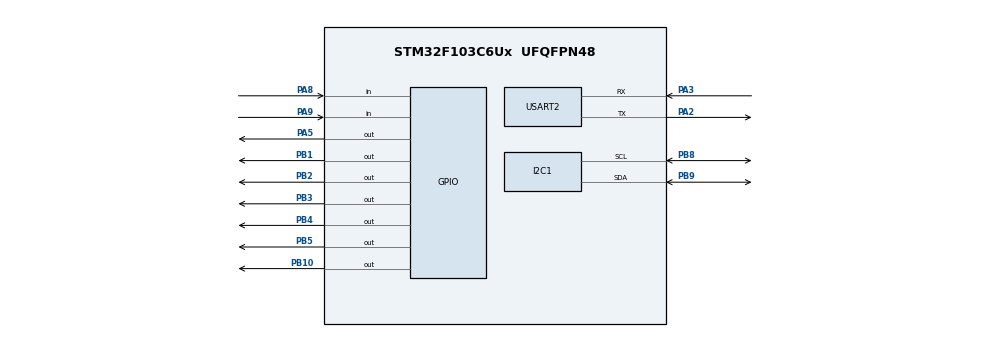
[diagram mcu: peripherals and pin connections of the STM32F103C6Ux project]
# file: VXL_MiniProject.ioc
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Mcu.Family=STM32F1
Mcu.Name=STM32F103C6Ux
Mcu.Package=UFQFPN48
NVIC.PriorityGroup=NVIC_PRIORITYGROUP_4
NVIC.TIM2_IRQn=true\:0\:0\:false\:false\:true\:true\:true\:true
NVIC.USART2_IRQn=true\:0\:0\:false\:false\:true\:true\:true\:true
PA2.Mode=Asynchronous
PA2.Signal=USART2_TX
PA3.Mode=Asynchronous
PA3.Signal=USART2_RX
PA5.Signal=GPIO_Output
PA8.GPIO_PuPd=GPIO_PULLUP
PA8.Signal=GPIO_Input
PA9.GPIO_PuPd=GPIO_PULLUP
PA9.Signal=GPIO_Input
PB1.Signal=GPIO_Output
PB10.Signal=GPIO_Output
PB2.Signal=GPIO_Output
PB3.Signal=GPIO_Output
PB4.Signal=GPIO_Output
PB5.Signal=GPIO_Output
PB8.Mode=I2C
PB8.Signal=I2C1_SCL
PB9.Mode=I2C
PB9.Signal=I2C1_SDA
ProjectManager.HeapSize=0x200
ProjectManager.StackSize=0x400
ProjectManager.TargetToolchain=STM32CubeIDE
RCC.APB1Freq_Value=8000000
RCC.APB2Freq_Value=8000000
TIM2.Period=9
TIM2.Prescaler=7999
USART2.VirtualMode=VM_ASYNC
VP_SYS_VS_ND.Mode=No_Debug
VP_TIM2_VS_ClockSourceINT.Mode=Internal
board=custom

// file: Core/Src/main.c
/* USER CODE BEGIN Header */
/**
  ******************************************************************************
  * @file           : main.c
  * @brief          : Main program body
  ******************************************************************************
  * @attention
  *
  * Copyright (c) 2025 STMicroelectronics.
  * All rights reserved.
  *
  * This software is licensed under terms that can be found in the LICENSE file
  * in the root directory of this software component.
  * If no LICENSE file comes with this software, it is provided AS-IS.
  *
  ******************************************************************************
  */
/* USER CODE END Header */
#include "main.h"

/* USER CODE BEGIN Includes */
#include "global.h"
/* USER CODE END Includes */

/* USER CODE BEGIN PD */
#define MyI2C_LCD I2C_LCD_1
/* USER CODE END PD */

I2C_HandleTypeDef hi2c1;

TIM_HandleTypeDef htim2;

UART_HandleTypeDef huart2;

void SystemClock_Config(void);
static void MX_GPIO_Init(void);
static void MX_TIM2_Init(void);
static void MX_USART2_UART_Init(void);
static void MX_I2C1_Init(void);

int main(void)
{

  /* MCU Configuration--------------------------------------------------------*/

  /* Reset of all peripherals, Initializes the Flash interface and the Systick. */
  HAL_Init();

  /* Configure the system clock */
  SystemClock_Config();

  /* Initialize all configured peripherals */
  MX_GPIO_Init();
  MX_TIM2_Init();
  MX_USART2_UART_Init();
  MX_I2C1_Init();
  /* USER CODE BEGIN 2 */
  HAL_TIM_Base_Start_IT (&htim2);
//  HAL_UART_Receive_IT(&huart2, rx_data, 1);
  /* USER CODE END 2 */

  /* Infinite loop */
  /* USER CODE BEGIN WHILE */
  SCH_Init();
  SCH_Add_Task(Run_Traffic_Light, 0, 100);
  HAL_GPIO_WritePin(GPIOA, LED_PINK, SET);
  while (1)
  {
//	  if (isButtonPressed(0) == 1){
//		  HAL_GPIO_TogglePin(GPIOA, LED_PINK);
//	  }
	  //HAL_GPIO_WritePin(GPIOA, LED_PINK, HAL_GPIO_ReadPin(GPIOA, UP_BUTTON));
//	  if (isButtonPressed(0) == 1){
//	  		  HAL_GPIO_TogglePin(GPIOA, LED_PINK);
//	  		  button_flag[0] = 0;
//	  	  }
	  SCH_Dispatch_Tasks();
//	  HAL_Delay(1000);
    /* USER CODE END WHILE */

  }
}

void SystemClock_Config(void)
{
  RCC_OscInitTypeDef RCC_OscInitStruct = {0};
  RCC_ClkInitTypeDef RCC_ClkInitStruct = {0};

  /** Initializes the RCC Oscillators according to the specified parameters
  * in the RCC_OscInitTypeDef structure.
  */
  RCC_OscInitStruct.OscillatorType = RCC_OSCILLATORTYPE_HSI;
  RCC_OscInitStruct.HSIState = RCC_HSI_ON;
  RCC_OscInitStruct.HSICalibrationValue = RCC_HSICALIBRATION_DEFAULT;
  RCC_OscInitStruct.PLL.PLLState = RCC_PLL_NONE;
  if (HAL_RCC_OscConfig(&RCC_OscInitStruct) != HAL_OK)
  {
    Error_Handler();
  }

  /** Initializes the CPU, AHB and APB buses clocks
  */
  RCC_ClkInitStruct.ClockType = RCC_CLOCKTYPE_HCLK|RCC_CLOCKTYPE_SYSCLK
                              |RCC_CLOCKTYPE_PCLK1|RCC_CLOCKTYPE_PCLK2;
  RCC_ClkInitStruct.SYSCLKSource = RCC_SYSCLKSOURCE_HSI;
  RCC_ClkInitStruct.AHBCLKDivider = RCC_SYSCLK_DIV1;
  RCC_ClkInitStruct.APB1CLKDivider = RCC_HCLK_DIV1;
  RCC_ClkInitStruct.APB2CLKDivider = RCC_HCLK_DIV1;

  if (HAL_RCC_ClockConfig(&RCC_ClkInitStruct, FLASH_LATENCY_0) != HAL_OK)
  {
    Error_Handler();
  }
}

static void MX_I2C1_Init(void)
{

  hi2c1.Instance = I2C1;
  hi2c1.Init.ClockSpeed = 100000;
  hi2c1.Init.DutyCycle = I2C_DUTYCYCLE_2;
  hi2c1.Init.OwnAddress1 = 0;
  hi2c1.Init.AddressingMode = I2C_ADDRESSINGMODE_7BIT;
  hi2c1.Init.DualAddressMode = I2C_DUALADDRESS_DISABLE;
  hi2c1.Init.OwnAddress2 = 0;
  hi2c1.Init.GeneralCallMode = I2C_GENERALCALL_DISABLE;
  hi2c1.Init.NoStretchMode = I2C_NOSTRETCH_DISABLE;
  if (HAL_I2C_Init(&hi2c1) != HAL_OK)
  {
    Error_Handler();
  }

}

static void MX_TIM2_Init(void)
{

  TIM_ClockConfigTypeDef sClockSourceConfig = {0};
  TIM_MasterConfigTypeDef sMasterConfig = {0};

  htim2.Instance = TIM2;
  htim2.Init.Prescaler = 7999;
  htim2.Init.CounterMode = TIM_COUNTERMODE_UP;
  htim2.Init.Period = 9;
  htim2.Init.ClockDivision = TIM_CLOCKDIVISION_DIV1;
  htim2.Init.AutoReloadPreload = TIM_AUTORELOAD_PRELOAD_DISABLE;
  if (HAL_TIM_Base_Init(&htim2) != HAL_OK)
  {
    Error_Handler();
  }
  sClockSourceConfig.ClockSource = TIM_CLOCKSOURCE_INTERNAL;
  if (HAL_TIM_ConfigClockSource(&htim2, &sClockSourceConfig) != HAL_OK)
  {
    Error_Handler();
  }
  sMasterConfig.MasterOutputTrigger = TIM_TRGO_RESET;
  sMasterConfig.MasterSlaveMode = TIM_MASTERSLAVEMODE_DISABLE;
  if (HAL_TIMEx_MasterConfigSynchronization(&htim2, &sMasterConfig) != HAL_OK)
  {
    Error_Handler();
  }

}

static void MX_USART2_UART_Init(void)
{

  huart2.Instance = USART2;
  huart2.Init.BaudRate = 115200;
  huart2.Init.WordLength = UART_WORDLENGTH_8B;
  huart2.Init.StopBits = UART_STOPBITS_1;
  huart2.Init.Parity = UART_PARITY_NONE;
  huart2.Init.Mode = UART_MODE_TX_RX;
  huart2.Init.HwFlowCtl = UART_HWCONTROL_NONE;
  huart2.Init.OverSampling = UART_OVERSAMPLING_16;
  if (HAL_UART_Init(&huart2) != HAL_OK)
  {
    Error_Handler();
  }

}

static void MX_GPIO_Init(void)
{
  GPIO_InitTypeDef GPIO_InitStruct = {0};

  /* GPIO Ports Clock Enable */
  __HAL_RCC_GPIOA_CLK_ENABLE();
  __HAL_RCC_GPIOB_CLK_ENABLE();

  /*Configure GPIO pin Output Level */
  HAL_GPIO_WritePin(GPIOA, GPIO_PIN_5, GPIO_PIN_RESET);

  /*Configure GPIO pin Output Level */
  HAL_GPIO_WritePin(GPIOB, GPIO_PIN_1|GPIO_PIN_2|GPIO_PIN_10|GPIO_PIN_3
                          |GPIO_PIN_4|GPIO_PIN_5, GPIO_PIN_RESET);

  /*Configure GPIO pin : PA5 */
  GPIO_InitStruct.Pin = GPIO_PIN_5;
  GPIO_InitStruct.Mode = GPIO_MODE_OUTPUT_PP;
  GPIO_InitStruct.Pull = GPIO_NOPULL;
  GPIO_InitStruct.Speed = GPIO_SPEED_FREQ_LOW;
  HAL_GPIO_Init(GPIOA, &GPIO_InitStruct);

  /*Configure GPIO pins : PB1 PB2 PB10 PB3
                           PB4 PB5 */
  GPIO_InitStruct.Pin = GPIO_PIN_1|GPIO_PIN_2|GPIO_PIN_10|GPIO_PIN_3
                          |GPIO_PIN_4|GPIO_PIN_5;
  GPIO_InitStruct.Mode = GPIO_MODE_OUTPUT_PP;
  GPIO_InitStruct.Pull = GPIO_NOPULL;
  GPIO_InitStruct.Speed = GPIO_SPEED_FREQ_LOW;
  HAL_GPIO_Init(GPIOB, &GPIO_InitStruct);

  /*Configure GPIO pins : PA8 PA9 */
  GPIO_InitStruct.Pin = GPIO_PIN_8|GPIO_PIN_9;
  GPIO_InitStruct.Mode = GPIO_MODE_INPUT;
  GPIO_InitStruct.Pull = GPIO_PULLUP;
  HAL_GPIO_Init(GPIOA, &GPIO_InitStruct);

}

/* USER CODE BEGIN 4 */
int counter = 100;
void HAL_TIM_PeriodElapsedCallback(TIM_HandleTypeDef *htim){
//	SCH_Update();
//	if (counter > 0){
//		counter--;
//		if (counter <= 0){
//			counter = 100;
//			HAL_GPIO_TogglePin(GPIOA, LED_PINK);
//		}
//	}
	SCH_Update();
	getKeyInput();
}

/* USER CODE END 4 */

void Error_Handler(void)
{
  __disable_irq();
  while (1)
  {
  }
}
